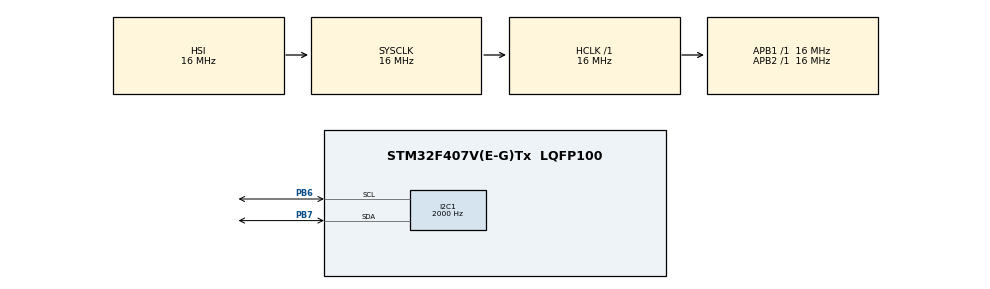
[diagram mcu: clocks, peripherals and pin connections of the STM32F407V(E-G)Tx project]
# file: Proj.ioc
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I2C1.ClockSpeed=2000
I2C1.OwnAddress=51
Mcu.Family=STM32F4
Mcu.Name=STM32F407V(E-G)Tx
Mcu.Package=LQFP100
NVIC.I2C1_ER_IRQn=true\:0\:0\:false\:false\:true\:true\:true
NVIC.I2C1_EV_IRQn=true\:0\:0\:false\:false\:true\:true\:true
NVIC.PriorityGroup=NVIC_PRIORITYGROUP_4
PB6.Mode=I2C
PB6.Signal=I2C1_SCL
PB7.Mode=I2C
PB7.Signal=I2C1_SDA
ProjectManager.HeapSize=0x200
ProjectManager.StackSize=0x400
ProjectManager.TargetToolchain=TrueSTUDIO
RCC.AHBFreq_Value=16000000
RCC.APB1Freq_Value=16000000
RCC.APB2Freq_Value=16000000
RCC.CortexFreq_Value=16000000
RCC.HSE_VALUE=25000000
RCC.HSI_VALUE=16000000
RCC.LSE_VALUE=32768
RCC.SYSCLKFreq_VALUE=16000000
RCC.VCOOutputFreq_Value=192000000
board=custom

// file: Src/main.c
/* USER CODE BEGIN Header */
/**
  ******************************************************************************
  * @file           : main.c
  * @brief          : Main program body
  ******************************************************************************
  * @attention
  *
  * <h2><center>&copy; Copyright (c) 2020 STMicroelectronics.
  * All rights reserved.</center></h2>
  *
  * This software component is licensed by ST under BSD 3-Clause license,
  * the "License"; You may not use this file except in compliance with the
  * License. You may obtain a copy of the License at:
  *                        opensource.org/licenses/BSD-3-Clause
  *
  ******************************************************************************
  */
/* USER CODE END Header */

#include "main.h"

/* USER CODE BEGIN Includes */
#include "I2CMng.h"
/* USER CODE END Includes */

I2C_HandleTypeDef hi2c1;

/* USER CODE BEGIN PV */
uint32_t _sysCounter100MSec;//до переполнения пройдет 13 лет ). использовать там где не нужна точность, плюс минус пол локтя..
uint32_t GetSysCounter100MSec(void){return _sysCounter100MSec;}
uint64_t _sysCounter1MSec;
uint64_t GetSysCounter1MSec(void){return _sysCounter1MSec;}
/* USER CODE END PV */

void SystemClock_Config(void);
static void MX_GPIO_Init(void);
static void MX_I2C1_Init(void);

/* USER CODE BEGIN 0 */
//uint8_t _aRxBuffer[10];
//uint8_t arrReadData[3] = {1, 2, 3};
/* USER CODE END 0 */

int main(void)
{

  /* MCU Configuration--------------------------------------------------------*/

  /* Reset of all peripherals, Initializes the Flash interface and the Systick. */
  HAL_Init();

  /* Configure the system clock */
  SystemClock_Config();

  /* Initialize all configured peripherals */
  MX_GPIO_Init();
  MX_I2C1_Init();

  /* Infinite loop */
  /* USER CODE BEGIN WHILE */
  I2CInit();
  while (1)
  {

	  I2CReceive(&hi2c1, 0);
	  I2CSend(&hi2c1, 0);
	  PrepData(0);
	  HAL_SYSTICK_Callback();//временно

    /* USER CODE END WHILE */

  }
}

void SystemClock_Config(void)
{
  RCC_OscInitTypeDef RCC_OscInitStruct = {0};
  RCC_ClkInitTypeDef RCC_ClkInitStruct = {0};

  /** Configure the main internal regulator output voltage
  */
  __HAL_RCC_PWR_CLK_ENABLE();
  __HAL_PWR_VOLTAGESCALING_CONFIG(PWR_REGULATOR_VOLTAGE_SCALE1);
  /** Initializes the CPU, AHB and APB busses clocks
  */
  RCC_OscInitStruct.OscillatorType = RCC_OSCILLATORTYPE_HSI;
  RCC_OscInitStruct.HSIState = RCC_HSI_ON;
  RCC_OscInitStruct.HSICalibrationValue = RCC_HSICALIBRATION_DEFAULT;
  RCC_OscInitStruct.PLL.PLLState = RCC_PLL_NONE;
  if (HAL_RCC_OscConfig(&RCC_OscInitStruct) != HAL_OK)
  {
    Error_Handler();
  }
  /** Initializes the CPU, AHB and APB busses clocks
  */
  RCC_ClkInitStruct.ClockType = RCC_CLOCKTYPE_HCLK|RCC_CLOCKTYPE_SYSCLK
                              |RCC_CLOCKTYPE_PCLK1|RCC_CLOCKTYPE_PCLK2;
  RCC_ClkInitStruct.SYSCLKSource = RCC_SYSCLKSOURCE_HSI;
  RCC_ClkInitStruct.AHBCLKDivider = RCC_SYSCLK_DIV1;
  RCC_ClkInitStruct.APB1CLKDivider = RCC_HCLK_DIV1;
  RCC_ClkInitStruct.APB2CLKDivider = RCC_HCLK_DIV1;

  if (HAL_RCC_ClockConfig(&RCC_ClkInitStruct, FLASH_LATENCY_0) != HAL_OK)
  {
    Error_Handler();
  }
}

static void MX_I2C1_Init(void)
{

  hi2c1.Instance = I2C1;
  hi2c1.Init.ClockSpeed = 1000;
  hi2c1.Init.DutyCycle = I2C_DUTYCYCLE_2;
  hi2c1.Init.OwnAddress1 = 102;
  hi2c1.Init.AddressingMode = I2C_ADDRESSINGMODE_7BIT;
  hi2c1.Init.DualAddressMode = I2C_DUALADDRESS_DISABLE;
  hi2c1.Init.OwnAddress2 = 0;
  hi2c1.Init.GeneralCallMode = I2C_GENERALCALL_ENABLE;
  hi2c1.Init.NoStretchMode = I2C_NOSTRETCH_DISABLE;
  if (HAL_I2C_Init(&hi2c1) != HAL_OK)
  {
    Error_Handler();
  }

}

static void MX_GPIO_Init(void)
{

  /* GPIO Ports Clock Enable */
  __HAL_RCC_GPIOB_CLK_ENABLE();

}

/* USER CODE BEGIN 4 */

void HAL_SYSTICK_Callback(void)
{
	static uint8_t sysTicksCnt4Get100MSec = 0;
	if((sysTicksCnt4Get100MSec++) >= 100)
	{
		sysTicksCnt4Get100MSec = 0;
		_sysCounter100MSec++;
	}
	_sysCounter1MSec++;
}
/* USER CODE END 4 */

void Error_Handler(void)
{
}

/************************ (C) COPYRIGHT STMicroelectronics *****END OF FILE****/
